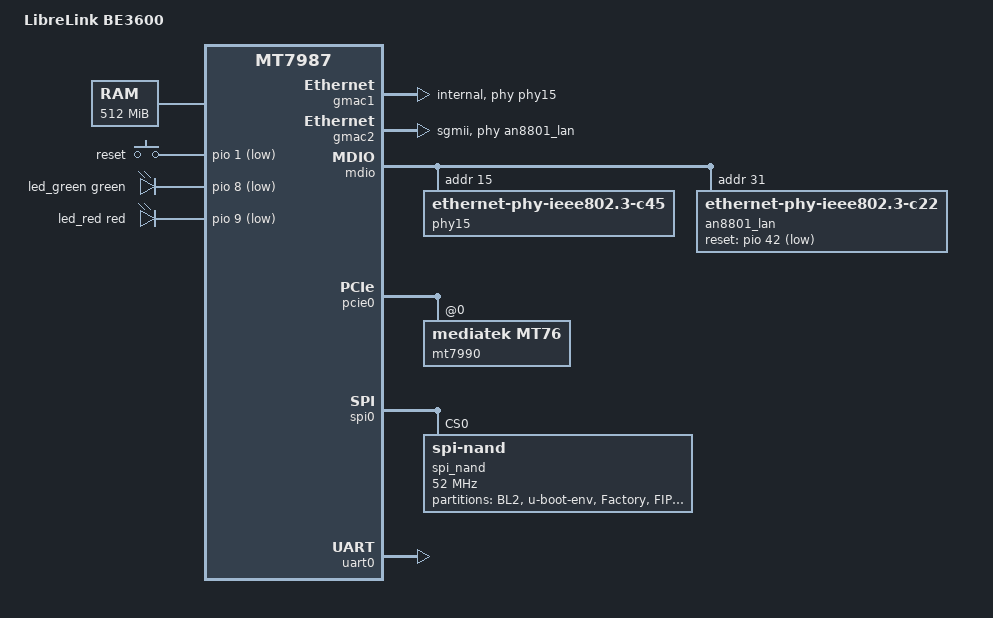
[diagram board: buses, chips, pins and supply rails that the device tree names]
// SPDX-License-Identifier: (GPL-2.0 OR MIT)

/dts-v1/;
#include "mt7987b.dtsi"
#include <dt-bindings/input/input.h>
#include <dt-bindings/leds/common.h>

/ {
	model = "LibreLink BE3600";
	compatible = "librelink,be3600",
		     "mediatek,mt7987b",
		     "mediatek,mt7987";

	aliases {
		serial0 = &uart0;
		label-mac-device = &gmac1;
		led-boot = &led_green;
		led-failsafe = &led_red;
		led-running = &led_green;
		led-upgrade = &led_green;
	};

	chosen {
		bootargs = "console=ttyS0,115200n1 \
			    earlycon=uart8250,mmio32,0x11000000 \
			    pci=pcie_bus_perf";
		rootdisk = <&ubi_fit>;
		stdout-path = "serial0:115200n8";
	};

	memory@40000000 {
		device_type = "memory";
		reg = <0x0 0x40000000 0x0 0x20000000>;
	};

	gpio-keys {
		compatible = "gpio-keys";

		reset {
			label = "reset";
			linux,code = <KEY_RESTART>;
			gpios = <&pio 1 GPIO_ACTIVE_LOW>;
			debounce-interval = <10>;
		};
	};

	leds {
		compatible = "gpio-leds";

		/*
		 * GPIO#8/GPIO#9 carry the net names SYS_LED_R/SYS_LED_G but the
		 * interface doc (GTW07A §2.1.3, §3.1) and the shipping board DTS
		 * both wire them to the green and the red element respectively.
		 */
		led_green: led-0 {
			color = <LED_COLOR_ID_GREEN>;
			function = LED_FUNCTION_STATUS;
			gpios = <&pio 8 GPIO_ACTIVE_LOW>;
		};

		led_red: led-1 {
			color = <LED_COLOR_ID_RED>;
			function = LED_FUNCTION_STATUS;
			gpios = <&pio 9 GPIO_ACTIVE_LOW>;
		};
	};
};

&gmac1 {
	nvmem-cells = <&macaddr_factory_24>;
	nvmem-cell-names = "mac-address";
	openwrt,netdev-name = "wan";
	phy-mode = "internal";
	phy-handle = <&phy15>;
	status = "okay";
};

&gmac2 {
	nvmem-cells = <&macaddr_factory_2a>;
	nvmem-cell-names = "mac-address";
	openwrt,netdev-name = "lan";
	phy-mode = "sgmii";
	phy-handle = <&an8801_lan>;
	managed = "in-band-status";
	status = "okay";
};

&mdio {
	phy15: phy@15 {
		compatible = "ethernet-phy-ieee802.3-c45";
		reg = <15>;

		pinctrl-0 = <&i2p5gbe_led0_pins>;
		pinctrl-names = "i2p5gbe-led";
	};

	an8801_lan: ethernet-phy@31 {
		/*
		 * BE3600 LAN can use AN8801S/EN8801S or AN8801/AN8801SB.
		 * Keep this as a probed C22 PHY so mounted alternatives such as
		 * YT8531A can bind to their native driver when present.
		 * The GPHY address is taken from the switch's own configuration
		 * (EN8801S strap GPIO#5 = 1, doc §2.3.1), not from the MDIO straps.
		 */
		compatible = "ethernet-phy-ieee802.3-c22";
		reg = <31>;
		phy-mode = "sgmii";
		reset-gpios = <&pio 42 GPIO_ACTIVE_LOW>;
		reset-assert-us = <10000>;
		reset-deassert-us = <10000>;
		eee-broken-100tx;
		eee-broken-1000t;
	};
};

&pcie0 {
	pinctrl-names = "default";
	pinctrl-0 = <&pcie0_pins>;
	status = "okay";

	pcie@0,0 {
		reg = <0x0000 0 0 0 0>;
		#address-cells = <3>;
		#size-cells = <2>;

		mt7990@0,0 {
			compatible = "mediatek,mt76";
			reg = <0x0000 0 0 0 0>;
			device_type = "pci";

			#address-cells = <1>;
			#size-cells = <0>;

			/* 2.4G/5G only: single-band antennas, MT7990 6 GHz front-end unpopulated */
			ieee80211-freq-limit = <2400000 2500000>,
					       <5170000 5835000>;

			nvmem-cells = <&eeprom_factory_0>;
			nvmem-cell-names = "eeprom";

			band@0 {
				reg = <0>;
				nvmem-cells = <&macaddr_factory_4>;
				nvmem-cell-names = "mac-address";
			};

			band@1 {
				reg = <1>;
				nvmem-cells = <&macaddr_factory_a>;
				nvmem-cell-names = "mac-address";
			};
		};
	};
};

&pcie1 {
	status = "disabled";
};

&spi0 {
	#address-cells = <1>;
	#size-cells = <0>;
	pinctrl-names = "default";
	pinctrl-0 = <&spi0_flash_pins>;
	status = "okay";

	spi_nand: flash@0 {
		compatible = "spi-nand";
		reg = <0>;
		spi-max-frequency = <52000000>;
		spi-tx-bus-width = <4>;
		spi-rx-bus-width = <4>;
		mediatek,nmbm;
		mediatek,bmt-max-ratio = <1>;
		mediatek,bmt-max-reserved-blocks = <64>;

		partitions {
			compatible = "fixed-partitions";
			#address-cells = <1>;
			#size-cells = <1>;

			partition@0 {
				label = "BL2";
				reg = <0x00000 0x0100000>;
				read-only;
			};

			partition@100000 {
				label = "u-boot-env";
				reg = <0x0100000 0x0080000>;
			};

			factory: partition@180000 {
				label = "Factory";
				reg = <0x180000 0x0400000>;
				read-only;

				nvmem-layout {
					compatible = "fixed-layout";
					#address-cells = <1>;
					#size-cells = <1>;

					eeprom_factory_0: eeprom@0 {
						reg = <0x0 0x1e00>;
					};

					macaddr_factory_4: macaddr@4 {
						reg = <0x4 0x6>;
					};

					macaddr_factory_a: macaddr@a {
						reg = <0xa 0x6>;
					};

					macaddr_factory_24: macaddr@24 {
						reg = <0x24 0x6>;
					};

					macaddr_factory_2a: macaddr@2a {
						reg = <0x2a 0x6>;
					};
				};
			};

			/* BL2 loads the FIP from 0x580000; keep in sync with its FIP_BASE. */
			partition@580000 {
				label = "FIP";
				reg = <0x580000 0x0200000>;
			};

			partition@780000 {
				label = "ubi";
				reg = <0x0780000 0x02000000>;
				compatible = "linux,ubi";

				volumes {
					ubi_env: ubi-volume-ubootenv {
						volname = "ubootenv";
					};

					ubi_env2: ubi-volume-ubootenv2 {
						volname = "ubootenv2";
					};

					ubi_fit: ubi-volume-fit {
						volname = "fit";
					};
				};
			};

			partition@2780000 {
				label = "ubi1";
				reg = <0x2780000 0x02000000>;
			};

			partition@4780000 {
				label = "cfg";
				reg = <0x4780000 0x00400000>;
			};

			partition@4b80000 {
				label = "cfg_backup";
				reg = <0x4b80000 0x00400000>;
			};

			partition@4f80000 {
				label = "product_info";
				reg = <0x4f80000 0x00080000>;
			};

			partition@5000000 {
				label = "key_log";
				reg = <0x5000000 0x00400000>;
			};

			partition@5400000 {
				label = "plugin";
				reg = <0x5400000 0x01c00000>;
			};

			/* 16MB at the end of the flash are left to NMBM */
		};
	};
};

&uart0 {
	pinctrl-names = "default";
	pinctrl-0 = <&uart0_pins>;
	status = "okay";
};

&ubi_env {
	nvmem-layout {
		compatible = "u-boot,env-redundant-bool-layout";
	};
};

&ubi_env2 {
	nvmem-layout {
		compatible = "u-boot,env-redundant-bool-layout";
	};
};
